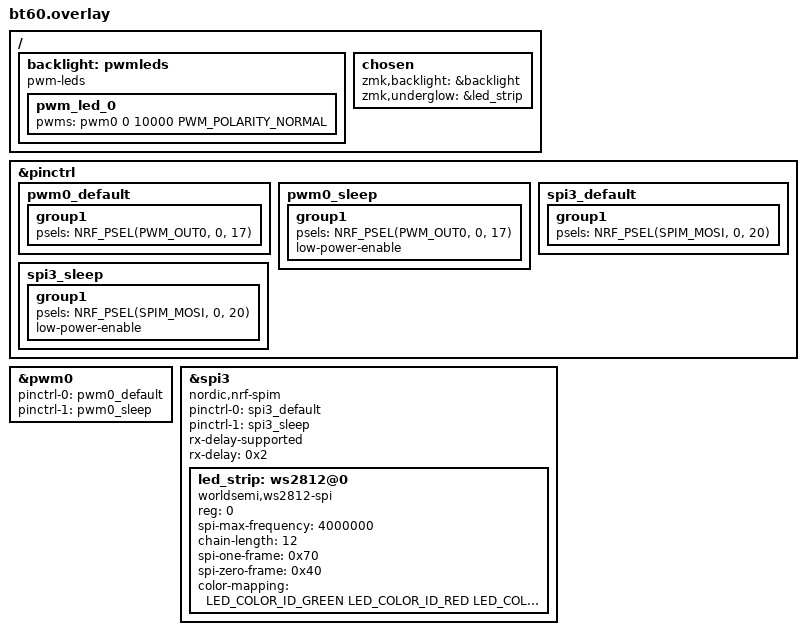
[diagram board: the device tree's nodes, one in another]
/*
 * Copyright (c) 2021 Polarity Works
 * SPDX-License-Identifier: MIT
 */

#include <dt-bindings/led/led.h>

&pinctrl {
    pwm0_default: pwm0_default {
        group1 {
            psels = <NRF_PSEL(PWM_OUT0, 0, 17)>;
        };
    };
    pwm0_sleep: pwm0_sleep {
        group1 {
            psels = <NRF_PSEL(PWM_OUT0, 0, 17)>;
            low-power-enable;
        };
    };
    spi3_default: spi3_default {
        group1 {
            psels = <NRF_PSEL(SPIM_MOSI, 0, 20)>;
        };
    };
    spi3_sleep: spi3_sleep {
        group1 {
            psels = <NRF_PSEL(SPIM_MOSI, 0, 20)>;
            low-power-enable;
        };
    };
};

&pwm0 {
    status = "okay";
    pinctrl-0 = <&pwm0_default>;
    pinctrl-1 = <&pwm0_sleep>;
    pinctrl-names = "default", "sleep";
};

/ {
    backlight: pwmleds {
        compatible = "pwm-leds";
        pwm_led_0 {
            pwms = <&pwm0 0 10000 PWM_POLARITY_NORMAL>;
        };
    };
};

&spi3 {
    compatible = "nordic,nrf-spim";
    pinctrl-0 = <&spi3_default>;
    pinctrl-1 = <&spi3_sleep>;
    pinctrl-names = "default", "sleep";
    status = "okay";
    rx-delay-supported;
    rx-delay = <0x2>;

    led_strip: ws2812@0 {
        compatible = "worldsemi,ws2812-spi";
        reg = <0>;
        spi-max-frequency = <4000000>;
        chain-length = <12>;
        spi-one-frame = <0x70>;
        spi-zero-frame = <0x40>;
        color-mapping = <LED_COLOR_ID_GREEN LED_COLOR_ID_RED LED_COLOR_ID_BLUE>;
    };
};

/ {
    chosen {
        zmk,backlight = &backlight;
        zmk,underglow = &led_strip;
    };
};
